VERSION ""

NS_ :

BS_ :

BU_ :

BO_ 1057 AEB11: 8 Vector__XXX
  SG_ AEB_Failinfo : 50|2@1+ (1,0) [0|0] "" Vector__XXX

BO_ 1 CAN1_Alive: 8 Vector__XXX
  SG_ CAN1_Alive : 0|8@1+ (1,0) [0|1000] "" Vector__XXX

BO_ 1345 CGW1: 8 Vector__XXX
 SG_ CF_Gway_IGNSw : 0|3@1+ (1,0) [0|7] ""  AFLS,CLU,EPB,LDWS_LKAS,MDPS
 SG_ CF_Gway_RKECmd : 3|3@1+ (1,0) [0|7] ""  CLU
 SG_ CF_Gway_DrvDrSw : 8|2@1+ (1,0) [0|3] ""  CLU,EPB,LDWS_LKAS,SCC
 SG_ CF_Gway_DrvSeatBeltSw : 10|2@1+ (1,0) [0|3] ""  EPB,LDWS_LKAS
 SG_ CF_Gway_TrunkTgSw : 12|2@1+ (1,0) [0|3] ""  CLU,EPB
 SG_ CF_Gway_SMKOption : 16|1@1+ (1,0) [0|1] ""  CLU
 SG_ CF_Gway_HoodSw : 17|2@1+ (1,0) [0|3] ""  CLU,EPB
 SG_ CF_Gway_TurnSigLh : 19|2@1+ (1,0) [0|3] ""  CLU,LCA,LDWS_LKAS,SCC
 SG_ CF_Gway_WiperIntT : 21|3@1+ (1,0) [0|7] ""  CLU,LDWS_LKAS
 SG_ CF_Gway_RainSnsState : 28|3@1+ (1,0) [0|7] ""  AFLS
 SG_ CF_Gway_HeadLampLow : 31|1@1+ (1,0) [0|1] ""  AFLS,CLU,LDWS_LKAS
 SG_ CF_Gway_HeadLampHigh : 32|1@1+ (1,0) [0|1] ""  AFLS,CLU,LDWS_LKAS
 SG_ CF_Gway_HazardSw : 33|2@1+ (1,0) [0|3] ""  LCA,LDWS_LKAS
 SG_ CF_Gway_AstDrSw : 35|1@1+ (1,0) [0|1] ""  CLU
 SG_ CF_Gway_LightSwState : 38|2@1+ (1,0) [0|3] ""  AFLS,CLU
 SG_ CF_Gway_TSigRHSw : 41|1@1+ (1,0) [0|1] ""  LDWS_LKAS
 SG_ CF_Gway_TSigLHSw : 42|1@1+ (1,0) [0|1] ""  LDWS_LKAS
 SG_ CF_Gway_DriveTypeOption : 43|1@1+ (1,0) [0|1] ""  CLU
 SG_ CF_Gway_PassiveAccessLock : 45|2@1+ (1,0) [0|3] ""  CLU
 SG_ CF_Gway_PassiveAccessUnlock : 48|2@1+ (1,0) [0|3] ""  CLU
 SG_ CF_Gway_PassingSW : 51|1@1+ (1,0) [0|1] ""  AFLS
 SG_ CF_Gway_HBAControlMode : 52|1@1+ (1,0) [0|1] ""  LDWS_LKAS
 SG_ CF_Gway_RainSnsOption : 56|1@1+ (1,0) [0|1] ""  CLU
 SG_ C_SunRoofOpenState : 57|1@1+ (1,0) [0|1] ""  CLU
 SG_ CF_Gway_TurnSigRh : 62|2@1+ (1,0) [0|3] ""  CLU,LCA,LDWS_LKAS,SCC

BO_ 1265 CLU11: 8 Vector__XXX
  SG_ CF_Clu_CruiseSwMain : 3|1@1+ (1,0) [0|0] "" Vector__XXX
  SG_ CF_Clu_CruiseSwState : 0|3@1+ (1,0) [0|0] "" Vector__XXX

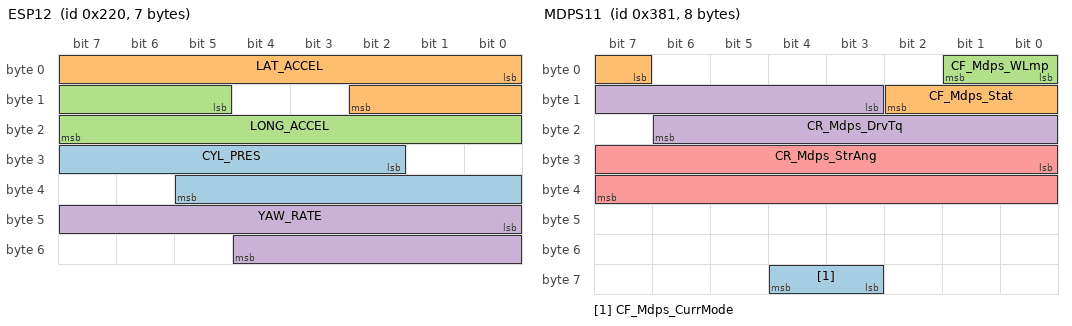
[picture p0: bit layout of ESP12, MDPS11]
BO_ 544 ESP12: 7 Vector__XXX
  SG_ CYL_PRES : 26|12@1+ (0.10000000000000001,0) [0|0] "bar" Vector__XXX
  SG_ LAT_ACCEL : 0|11@1+ (0.01,-10.23) [0|0] "m/s^2" Vector__XXX
  SG_ LONG_ACCEL : 13|11@1+ (0.01,-10.23) [0|0] "m/s^2" Vector__XXX
  SG_ YAW_RATE : 40|13@1+ (0.01,-40.950000000000003) [0|0] "deg/s" Vector__XXX

BO_ 1322 Gear_Statue: 8 Vector__XXX
  SG_ Gear : 8|8@1+ (1,0) [0|0] "" Vector__XXX

BO_ 897 MDPS11: 8 Vector__XXX
  SG_ CF_Mdps_CurrMode : 59|2@1+ (1,0) [0|0] "" Vector__XXX
  SG_ CF_Mdps_Stat : 7|4@1+ (1,0) [0|0] "" Vector__XXX
  SG_ CF_Mdps_WLmp : 0|2@1+ (1,0) [0|0] "" Vector__XXX
  SG_ CR_Mdps_DrvTq : 11|12@1+ (0.01,-20.48) [0|0] "" Vector__XXX
  SG_ CR_Mdps_StrAng : 24|16@1- (0.10000000000000001,0) [0|0] "" Vector__XXX

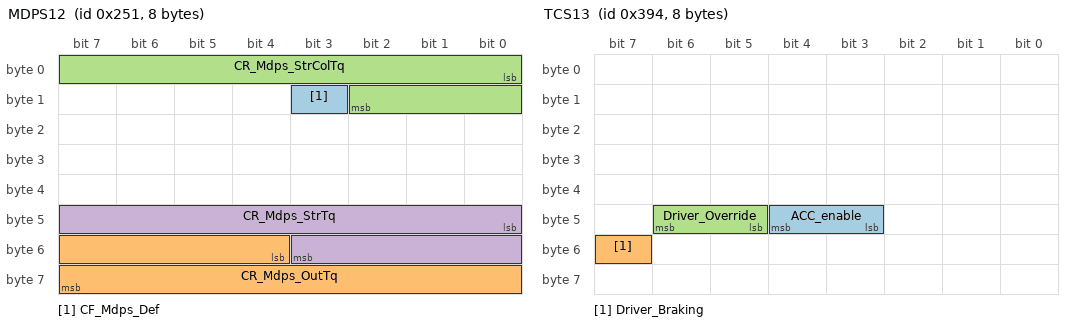
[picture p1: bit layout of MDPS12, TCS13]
BO_ 593 MDPS12: 8 Vector__XXX
  SG_ CF_Mdps_Def : 11|1@1+ (1,0) [0|0] "" Vector__XXX
  SG_ CR_Mdps_OutTq : 52|12@1+ (0.10000000000000001,-204.80000000000001) [0|0] "" Vector__XXX
  SG_ CR_Mdps_StrColTq : 0|11@1+ (0.0080000000000000002,-8) [0|0] "Nm" Vector__XXX
  SG_ CR_Mdps_StrTq : 40|12@1+ (0.01,-20.48) [0|0] "Nm" Vector__XXX

BO_ 688 SAS11: 5 Vector__XXX
  SG_ SAS_Angle : 0|16@1- (0.10000000000000001,0) [0|0] "Deg" Vector__XXX
  SG_ SAS_Speed : 16|8@1+ (4,0) [0|0] "" Vector__XXX

BO_ 916 TCS13: 8 Vector__XXX
  SG_ ACC_enable : 43|2@1+ (1,0) [0|0] "" Vector__XXX
  SG_ Driver_Braking : 55|1@1+ (1,0) [0|0] "" Vector__XXX
  SG_ Driver_Override : 45|2@1+ (1,0) [0|0] "" Vector__XXX

BO_ 1287 TCS15: 4 Vector__XXX
  SG_ ESC_Off_Step : 8|2@1+ (1,0) [0|0] "" Vector__XXX

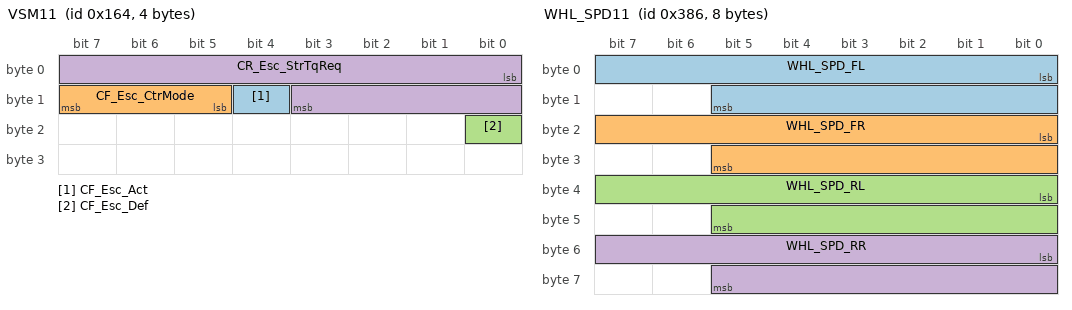
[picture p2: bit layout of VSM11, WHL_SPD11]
BO_ 356 VSM11: 4 Vector__XXX
  SG_ CF_Esc_Act : 12|1@1+ (1,0) [0|0] "" Vector__XXX
  SG_ CF_Esc_CtrMode : 13|3@1+ (1,0) [0|0] "" Vector__XXX
  SG_ CF_Esc_Def : 16|1@1+ (1,0) [0|0] "" Vector__XXX
  SG_ CR_Esc_StrTqReq : 0|12@1+ (0.01,-20.48) [0|0] "Nm" Vector__XXX

BO_ 902 WHL_SPD11: 8 Vector__XXX
  SG_ WHL_SPD_FL : 0|14@1+ (0.03125,0) [0|0] "km/h" Vector__XXX
  SG_ WHL_SPD_FR : 16|14@1+ (0.03125,0) [0|0] "km/h" Vector__XXX
  SG_ WHL_SPD_RL : 32|14@1+ (0.03125,0) [0|0] "km/h" Vector__XXX
  SG_ WHL_SPD_RR : 48|14@1+ (0.03125,0) [0|0] "km/h" Vector__XXX

BO_ 304 YRS11: 8 Vector__XXX
  SG_ CR_Yrs_LatAc : 16|16@1+ (0.000127465,-4.1767700000000003) [0|0] "g" Vector__XXX
  SG_ CR_Yrs_Yr : 0|16@1+ (0.0050000000000000001,-163.84) [0|0] "" Vector__XXX

BO_ 320 YRS12: 8 Vector__XXX
  SG_ CF_Yrs_Ax : 0|16@1+ (0.00012764499999999991,-4.1767700000000003) [0|0] "" Vector__XXX

BA_DEF_ "DBName" STRING;
BA_DEF_ "BusType" STRING;
BA_DEF_ BO_ "VFrameFormat" ENUM "StandardCAN","ExtendedCAN","reserved","J1939PG","reserved","reserved","reserved","reserved","reserved","reserved","reserved","reserved","reserved","reserved","StandardCAN_FD","ExtendedCAN_FD";
BA_DEF_ BO_ "GenMsgSendType" ENUM "Cyclic","Event","CyclicIfActive","SpontanWithDelay","CyclicAndSpontan","CyclicAndSpontanWithDelay";
BA_DEF_ BO_ "GenMsgCycleTime" INT 0 0;
BA_DEF_ SG_ "GenSigStartValue" FLOAT 0 0;
BA_DEF_DEF_ "DBName" "Cluster";
BA_DEF_DEF_ "BusType" "CAN";
BA_DEF_DEF_ "VFrameFormat" "StandardCAN";
BA_DEF_DEF_ "GenMsgSendType" "Cyclic";
BA_DEF_DEF_ "GenMsgCycleTime" 0;
BA_DEF_DEF_ "GenSigStartValue" 0;
BA_ "GenMsgSendType" BO_ 1057 1;
BA_ "GenMsgSendType" BO_ 1 1;
BA_ "GenMsgCycleTime" BO_ 1345 100;
BA_ "GenMsgSendType" BO_ 1265 1;
BA_ "GenMsgSendType" BO_ 544 1;
BA_ "GenMsgSendType" BO_ 1322 1;
BA_ "GenMsgSendType" BO_ 897 1;
BA_ "GenMsgSendType" BO_ 593 1;
BA_ "GenMsgSendType" BO_ 688 1;
BA_ "GenMsgSendType" BO_ 916 1;
BA_ "GenMsgSendType" BO_ 1287 1;
BA_ "GenMsgSendType" BO_ 356 1;
BA_ "GenMsgSendType" BO_ 902 1;
BA_ "GenMsgSendType" BO_ 304 1;
BA_ "GenMsgSendType" BO_ 320 1;
BA_ "GenSigStartValue" SG_ 544 LAT_ACCEL 1023;
BA_ "GenSigStartValue" SG_ 544 LONG_ACCEL 1023;
BA_ "GenSigStartValue" SG_ 544 YAW_RATE 4095;
BA_ "GenSigStartValue" SG_ 897 CR_Mdps_DrvTq 2048;
BA_ "GenSigStartValue" SG_ 593 CR_Mdps_OutTq 2048;
BA_ "GenSigStartValue" SG_ 593 CR_Mdps_StrColTq 1000;
BA_ "GenSigStartValue" SG_ 593 CR_Mdps_StrTq 2048;
BA_ "GenSigStartValue" SG_ 356 CR_Esc_StrTqReq 2048;
BA_ "GenSigStartValue" SG_ 304 CR_Yrs_LatAc 32767.975522692504;
BA_ "GenSigStartValue" SG_ 304 CR_Yrs_Yr 32768;
BA_ "GenSigStartValue" SG_ 320 CF_Yrs_Ax 32721.767401778397;
